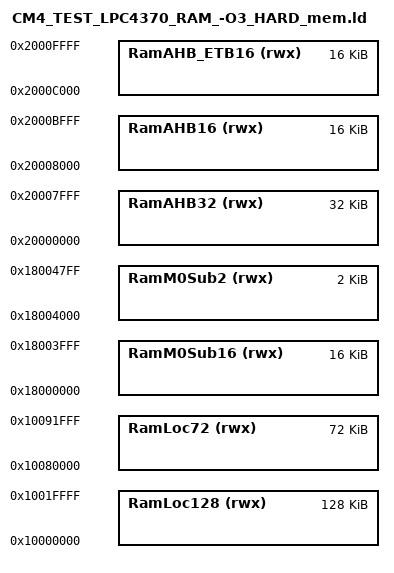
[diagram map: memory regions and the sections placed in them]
/*
 * GENERATED FILE - DO NOT EDIT
 * (c) Code Red Technologies Ltd, 2008-2015
 * (c) NXP Semiconductors 2013-2015
 * Linker script memory definitions
 * Created from LinkMemoryTemplate
 * By LPCXpresso v7.7.2 [Build 379] [2015-03-31]  on Sat Apr 18 09:05:19 EDT 2015)
*/

MEMORY
{
  /* Define each memory region */
  RamLoc128 (rwx) : ORIGIN = 0x10000000, LENGTH = 0x20000 /* 128K bytes */
  RamLoc72 (rwx) : ORIGIN = 0x10080000, LENGTH = 0x12000 /* 72K bytes */
  RamAHB32 (rwx) : ORIGIN = 0x20000000, LENGTH = 0x8000 /* 32K bytes */
  RamAHB16 (rwx) : ORIGIN = 0x20008000, LENGTH = 0x4000 /* 16K bytes */
  RamAHB_ETB16 (rwx) : ORIGIN = 0x2000c000, LENGTH = 0x4000 /* 16K bytes */
  RamM0Sub16 (rwx) : ORIGIN = 0x18000000, LENGTH = 0x4000 /* 16K bytes */
  RamM0Sub2 (rwx) : ORIGIN = 0x18004000, LENGTH = 0x800 /* 2K bytes */


}
  /* Define a symbol for the top of each memory region */
  __top_RamLoc128 = 0x10000000 + 0x20000;
  __top_RamLoc72 = 0x10080000 + 0x12000;
  __top_RamAHB32 = 0x20000000 + 0x8000;
  __top_RamAHB16 = 0x20008000 + 0x4000;
  __top_RamAHB_ETB16 = 0x2000c000 + 0x4000;
  __top_RamM0Sub16 = 0x18000000 + 0x4000;
  __top_RamM0Sub2 = 0x18004000 + 0x800;



